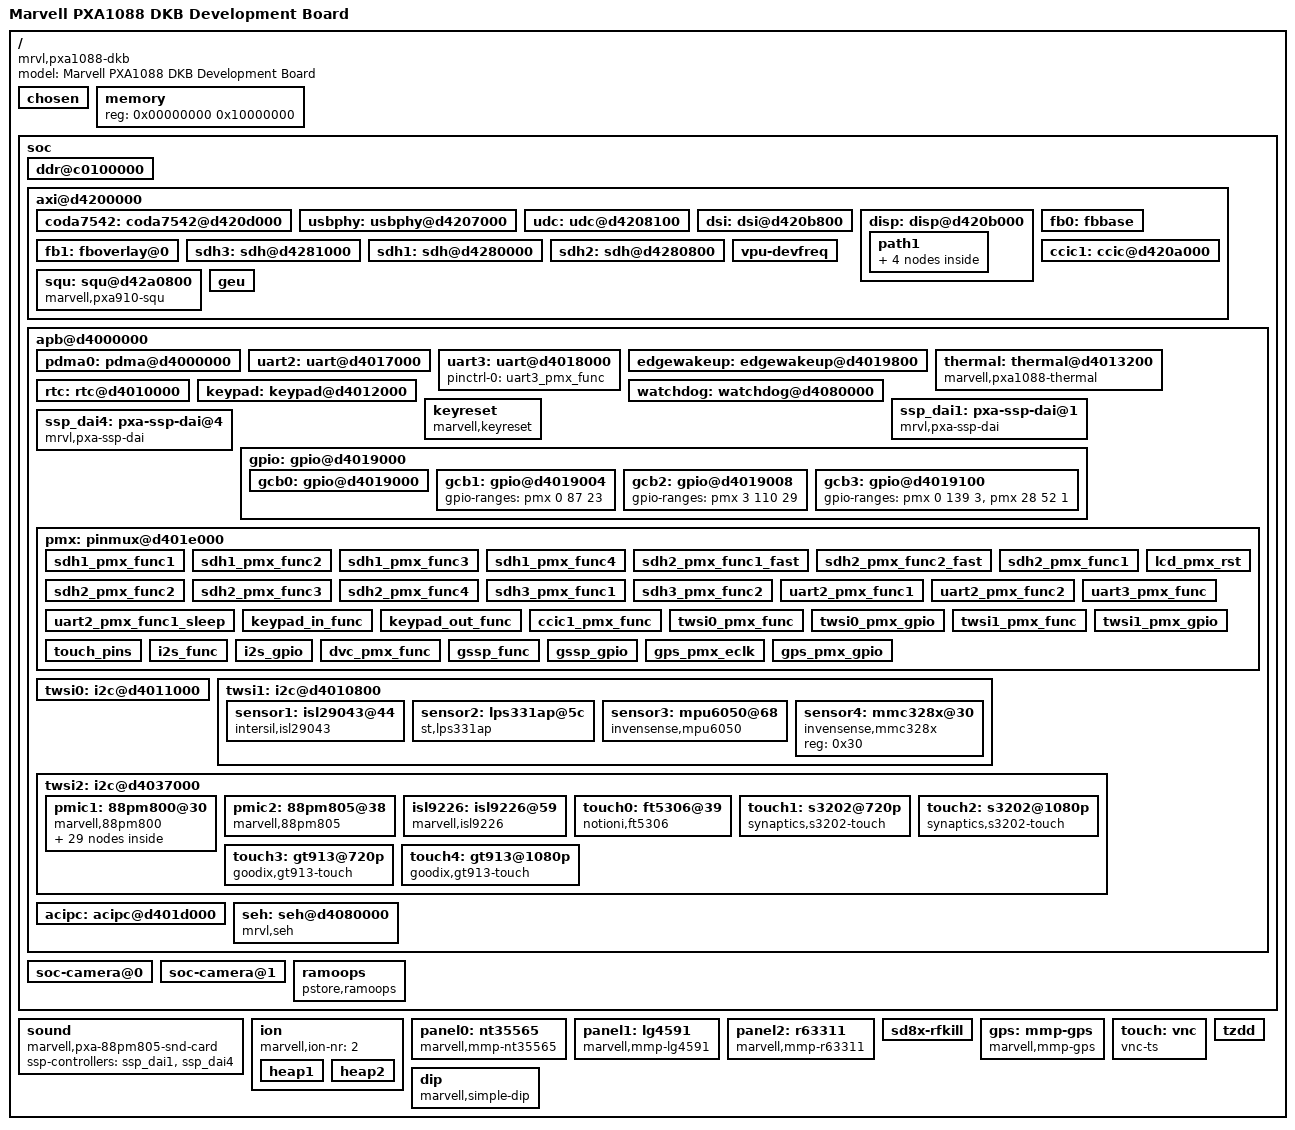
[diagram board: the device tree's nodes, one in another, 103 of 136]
/*
 *  Copyright (C) 2012 Marvell Technology Group Ltd.
 *  Author: Haojian Zhuang <haojian.zhuang@marvell.com>
 *
 *  This program is free software; you can redistribute it and/or modify
 *  it under the terms of the GNU General Public License version 2 as
 *  publishhed by the Free Software Foundation.
 */

/dts-v1/;
/memreserve/ 0x09000000 0x01000000;	/* ION (16MB)*/
/memreserve/ 0x17000000 0x01800000;	/* Frame buffer (24MB) */
/memreserve/ 0x08100000 0x00040000;    /* ramoops buffer (256KB) */
#include "pxa1088.dtsi"
#include <dt-bindings/mmc/pxa_sdhci.h>

/ {
	model = "Marvell PXA1088 DKB Development Board";
	compatible = "mrvl,pxa1088-dkb", "mrvl,pxa1088";

	chosen {
		bootargs = "console=ttyS0,115200 root=/dev/nfs nfsroot=192.168.1.100:/nfsroot/ ip=192.168.1.101:192.168.1.100::255.255.255.0::eth0:on";
	};

	memory {
		reg = <0x00000000 0x10000000>;
	};

	soc {
		ddr@c0100000 {  /* DDR memory controller */
			status = "okay";
		};

		axi@d4200000 {	/* AXI */
			coda7542: coda7542@d420d000 {
				marvell,sram-internal = <1>;
				marvell,nv21_support = <0>;
				status = "okay";
			};

			usbphy: usbphy@d4207000 {
				status = "okay";
			};

			udc: udc@d4208100 {
				status = "okay";
			};

			dsi: dsi@d420b800 {
				marvell,phy-name = "mmp_dsi1";
				marvell,plat-path-name = "mmp_pnpath";
				marvell,dsi-lanes = <2>;
				marvell,burst-mode = <2>;
				marvell,hbp-en;
				status = "okay";
			};

			disp: disp@d420b000 {
				marvell,disp-name = "disp_name";
				marvell,path-num = <1>;
				lpm-qos-d1p = <PM_QOS_CPUIDLE_BLOCK_AXI>;
				status = "okay";
				path1 {
					marvell,path-name = "mmp_pnpath";
					marvell,overlay-num = <2>;
					marvell,overlay-table = <0>, <1>;
					marvell,output-type = <1>;
					marvell,path-config = <0x10>;
					marvell,link-config = <0x1>;
					1080p {
						disp1_clksrc = "pll1_416m";
						dsipll_clksrc = "pll1_832m";
						pn_sclk_clksrc = "dsi_pll";
					};
					720p {
						disp1_clksrc = "pll1_416m";
						dsipll_clksrc = "pll3";
						pn_sclk_clksrc = "disp1";
					};
					qhd {
						disp1_clksrc = "pll1_416m";
						dsipll_clksrc = "pll3";
						pn_sclk_clksrc = "disp1";
					};
					WVGA {
						disp1_clksrc = "pll1_416m";
						dsipll_clksrc = "pll3";
						pn_sclk_clksrc = "dsi_pll";
					};
				};
			};

			fb0: fbbase {
				marvell,fb-name = "mmp-fb";
				marvell,path-name = "mmp_pnpath";
				marvell,overlay-id = <1>;
				marvell,default-pixfmt = <0x108>;
				marvell,buffer-num = <3>;
				marvell,fb-mem = <0x17000000 0x1800000>;
				status = "okay";
			};

			fb1: fboverlay@0 {
				marvell,fb-name = "mmp-fb-overlay.0";
				marvell,path-name = "mmp_pnpath";
				marvell,overlay-id = <0>;
				status = "okay";
			};

			/* eMMC */
			sdh3: sdh@d4281000 {
				pinctrl-names = "default";
				pinctrl-0 = <&sdh3_pmx_func1 &sdh3_pmx_func2>;
				bus-width = <8>;
				non-removable;
				marvell,sdh-pm-runtime-en;
				marvell,sdh-quirks = <(
						SDHCI_QUIRK_BROKEN_ADMA |
						SDHCI_QUIRK_BROKEN_CARD_DETECTION
						)>;
				marvell,sdh-quirks2 = <(SDHCI_QUIRK2_BUS_CLK_GATE_ENABLED)>;
				marvell,sdh-host-caps = <(MMC_CAP_1_8V_DDR)>;
				marvell,sdh-host-caps2 = <(MMC_CAP2_DISABLE_BLK_ASYNC)>;
				marvell,sdh-flags = <(
						PXA_FLAG_SD_8_BIT_CAPABLE_SLOT |
						PXA_FLAG_ENABLE_CLOCK_GATING |
						PXA_FLAG_TX_SEL_BUS_CLK
					      )>;
				/* prop "sdh-dtr-data": <timing preset_rate src_rate tx_delay rx_delay> */
				marvell,sdh-dtr-data = <PXA_MMC_TIMING_LEGACY PXA_SDH_DTR_26M PXA_SDH_DTR_104M 0 0>,
						<PXA_MMC_TIMING_MMC_HS PXA_SDH_DTR_52M PXA_SDH_DTR_104M 0 0>,
						<PXA_MMC_TIMING_UHS_DDR50 PXA_SDH_DTR_52M PXA_SDH_DTR_104M 0xd4 0>,
						<PXA_MMC_TIMING_MAX PXA_SDH_DTR_PS_NONE PXA_SDH_DTR_104M 0 0>;
				status = "okay";
			};

			/* SD card */
			sdh1: sdh@d4280000 {
				pinctrl-names = "default";
				pinctrl-0 = <&sdh1_pmx_func1 &sdh1_pmx_func2 &sdh1_pmx_func3 &sdh1_pmx_func4>;
				vqmmc-supply	= <&ldo12>;
				vmmc-supply	= <&ldo13>;
				cd-gpios = <&gpio 91 0>;
				cd-inverted;
				bus-width = <4>;
				wp-inverted;
				marvell,sdh-pm-runtime-en;
				marvell,sdh-host-caps-disable = <(MMC_CAP_UHS_SDR104)>;
				marvell,sdh-quirks = <(
						SDHCI_QUIRK_INVERTED_WRITE_PROTECT |
						SDHCI_QUIRK_BROKEN_CARD_DETECTION
						)>;
				marvell,sdh-quirks2 = <(SDHCI_QUIRK2_BUS_CLK_GATE_ENABLED)>;
				marvell,sdh-flags = <(
						PXA_FLAG_TX_SEL_BUS_CLK |
						PXA_FLAG_ENABLE_CLOCK_GATING
					      )>;
				/* prop "sdh-dtr-data": <timing preset_rate src_rate tx_delay rx_delay> */
				marvell,sdh-dtr-data = <PXA_MMC_TIMING_LEGACY PXA_SDH_DTR_26M PXA_SDH_DTR_104M 0 0>,
						<PXA_MMC_TIMING_SD_HS PXA_SDH_DTR_52M PXA_SDH_DTR_104M 0 0>,
						<PXA_MMC_TIMING_UHS_DDR50 PXA_SDH_DTR_52M PXA_SDH_DTR_104M 0 0>,
						<PXA_MMC_TIMING_MAX PXA_SDH_DTR_PS_NONE PXA_SDH_DTR_104M 0 0>;
				status = "okay";
			};

			/* SDIO */
			sdh2: sdh@d4280800 {
				pinctrl-names = "default", "fast";
				pinctrl-0 = <&sdh2_pmx_func1 &sdh2_pmx_func2 &sdh2_pmx_func3 &sdh2_pmx_func4>;
				pinctrl-1 = <&sdh2_pmx_func1_fast &sdh2_pmx_func2_fast &sdh2_pmx_func3 &sdh2_pmx_func4>;
				bus-width = <4>;
				marvell,sdh-quirks = <(SDHCI_QUIRK_BROKEN_CARD_DETECTION)>;
				marvell,sdh-quirks2 = <(
						SDHCI_QUIRK2_BUS_CLK_GATE_ENABLED |
						SDHCI_QUIRK2_SDIO_SW_CLK_GATE
						)>;
				marvell,sdh-pm-caps = <(MMC_PM_KEEP_POWER)>;
				marvell,sdh-host-caps2 = <(MMC_CAP2_NO_VOLTAGE_SWITCH)>;
				marvell,sdh-flags = <(
						PXA_FLAG_WAKEUP_HOST |
						PXA_FLAG_ENABLE_CLOCK_GATING |
						PXA_FLAG_TX_SEL_BUS_CLK |
						PXA_FLAG_EN_PM_RUNTIME |
						PXA_FLAG_DISABLE_PROBE_CDSCAN
					      )>;
				/* prop "sdh-dtr-data": <timing preset_rate src_rate tx_delay rx_delay> */
				marvell,sdh-dtr-data = <PXA_MMC_TIMING_LEGACY PXA_SDH_DTR_26M PXA_SDH_DTR_104M 0 0>,
						<PXA_MMC_TIMING_SD_HS PXA_SDH_DTR_45M PXA_SDH_DTR_89M 0 0>,
						<PXA_MMC_TIMING_MAX PXA_SDH_DTR_PS_NONE PXA_SDH_DTR_89M 0 0>;
				status = "okay";
			};

			ccic1: ccic@d420a000 {
				 pinctrl-names = "default";
				 pinctrl-0 = <&ccic1_pmx_func>;
				 pwdn-gpios = <&gpio 80 0>;
				 reset-gpios = <&gpio 81 0>;
				 af_2v8-supply = <&ldo17>;
				 avdd_2v8-supply = <&ldo16>;
				 status = "okay";
			};

			squ: squ@d42a0800 {
				compatible = "marvell,pxa910-squ";
				reg = <0xd42a0800 0x100>;
				interrupts = <0 46 0x4>;
				#dma-cells = <1>;
				asram = <&sram>;
			};
			vpu-devfreq {
				status = "okay";
			};
			geu: geu {
				status = "okay";
			};
		};

		apb@d4000000 {
			pdma0: pdma@d4000000 {
				status = "okay";
			};

			uart2: uart@d4017000 {
				pinctrl-names = "default", "sleep";
				pinctrl-0 = <&uart2_pmx_func1 &uart2_pmx_func2>;
				pinctrl-1 = <&uart2_pmx_func1_sleep &uart2_pmx_func2>;
				edge-wakeup-gpio = <47>; /* GPIO47: UART rx pin */
				status = "okay";
			};

			uart3: uart@d4018000 {
				pinctrl-names = "default";
				pinctrl-0 = <&uart3_pmx_func>;
				status = "okay";
			};

			edgewakeup: edgewakeup@d4019800 {
				status = "okay";
			};

			thermal: thermal@d4013200 {
				compatible = "marvell,pxa1088-thermal";
				reg = <0xd4013200 0x50>;
				interrupts = <0 60 0x4>;
				status = "ok";
			};

			rtc: rtc@d4010000 {
				status = "okay";
			};

			watchdog: watchdog@d4080000 {
				status = "okay";
			};

			keypad: keypad@d4012000 {
				keypad,num-rows = <4>;
				keypad,num-columns = <8>;
				linux,keymap = <0x0000000e
						0x0001008b
						0x000200d4
						0x0100008b
						0x01010066
						0x010200d4
						0x020000e7
						0x020100d9
						0x020200f0
						0x03000073
						0x03010072
						0x030200f0>;
				marvell,debounce-interval = <30>;
				pinctrl-names = "default";
				pinctrl-0 = <&keypad_in_func  &keypad_out_func>;
				status = "okay";
			};

			keyreset {
				compatible = "marvell,keyreset";
				keys-down = <0x73 0x72>;
				keyreset-need-panic;
			};

			ssp_dai1: pxa-ssp-dai@1 {
				compatible = "mrvl,pxa-ssp-dai";
				reg = <0x1 0x0>;
				port = <&ssp1>;
				pinctrl-names = "default","ssp";
				pinctrl-0 = <&i2s_gpio>;
				pinctrl-1 = <&i2s_func>;
				ssp-gpio = <&gpio 21 0 &gpio 22 0 &gpio 23 0 &gpio 24 0>;
				dmas = <&squ 1
					&squ 0>;
				dma-names = "rx", "tx";
				asram = <&sram>;
				platform_driver_name = "tdma_platform";
				burst_size = <4>;
				playback_period_bytes = <4096>;
				playback_buffer_bytes = <20480>;
				capture_period_bytes = <4096>;
				capture_buffer_bytes = <20480>;
			};

			ssp_dai4: pxa-ssp-dai@4 {
				compatible = "mrvl,pxa-ssp-dai";
				reg = <0x4 0x0>;
				port = <&ssp4>;
				pinctrl-names = "default","ssp";
				pinctrl-0 = <&gssp_gpio>;
				pinctrl-1 = <&gssp_func>;
				ssp-gpio = <&gpio 25 0 &gpio 26 0 &gpio 27 0 &gpio 28 0>;
				dmas = <&pdma0 6 0
					&pdma0 7 0>;
				dma-names = "rx", "tx";
				platform_driver_name = "pdma_platform";
				burst_size = <8>;
				playback_period_bytes = <4096>;
				playback_buffer_bytes = <131072>;
				capture_period_bytes = <4096>;
				capture_buffer_bytes = <131072>;
			};

			gpio: gpio@d4019000 {
				status = "okay";
				/*
				 * In theorical, some gpios could be routed to
				 * multiple pins. So define the gpio-ranges in
				 * board file, not silicon file.
				 */
				gcb0: gpio@d4019000 {
					/* gpio offset, pin offset, nr pins */
					gpio-ranges = <&pmx 0 55 1 &pmx 1 30 1 &pmx 2 57 30>;
				};
				gcb1: gpio@d4019004 {
					gpio-ranges = <&pmx 0 87 23>;
				};
				gcb2: gpio@d4019008 {
					gpio-ranges = <&pmx 3 110 29>;
				};
				gcb3: gpio@d4019100 {
					gpio-ranges = <&pmx 0 139 3  &pmx 28 52 1>;
				};
			};
			pmx: pinmux@d401e000 {
				/* pin base, nr pins & gpio function */
				pinctrl-single,gpio-range = <
					/*
					 * GPIO number is hardcoded for range at here.
					 * In gpio chip, GPIO number is not hardcoded for range.
					 * Since one gpio pin may be routed to multiple pins,
					 * define these gpio range in pxa910-dkb.dts not pxa910.dtsi.
					 */
					&range 55 1 0	/* GPIO0 */
					&range 30 1 1	/* GPIO1 */
					&range 57 53 0	/* GPIO2 ~ GPIO54 */
					&range 110 32 0 /* GPIO67 ~ GPIO98 */
					&range 52 1 0	/* GPIO124 */
				>;

				/* MFP_PULL_LOW | MFP_LPM_FLOAT */
				sdh1_pmx_func1: sdh1_pmx_func1 {
					pinctrl-single,pins = <
						MMC1_DAT7 AF0
						MMC1_DAT6 AF0
						MMC1_DAT5 AF0
						MMC1_DAT4 AF0
						MMC1_WP AF0
					>;
					DS_MEDIUM;PULL_DOWN;EDGE_NONE;LPM_FLOAT;
				};

				/* no pull, no LPM */
				sdh1_pmx_func2: sdh1_pmx_func2 {
					pinctrl-single,pins = <
						MMC1_DAT3 AF0
						MMC1_DAT2 AF0
						MMC1_DAT1 AF0
						MMC1_DAT0 AF0
						MMC1_CMD AF0
					>;
					MFP_DEFAULT;
				};

				/* MFP_LPM_DRIVE_LOW */
				sdh1_pmx_func3: sdh1_pmx_func3 {
					pinctrl-single,pins = <
						MMC1_CLK AF0
					>;
					MFP_LPM_DRIVE_LOW;
				};

				/* MFP_PULL_HIGH */
				sdh1_pmx_func4: sdh1_pmx_func4 {
					pinctrl-single,pins = <
						MMC1_CD AF0
					>;
					DS_MEDIUM;PULL_HIGH;EDGE_NONE;LPM_NONE;
				};

				sdh2_pmx_func1_fast: sdh2_pmx_func1_fast {
						pinctrl-single,pins = <
							GPIO37 AF1
							GPIO38 AF1
							GPIO39 AF1
							GPIO40 AF1
							GPIO41 AF1
						>;
						DS_FAST;PULL_NONE;EDGE_NONE;LPM_NONE;
				};

				sdh2_pmx_func2_fast: sdh2_pmx_func2_fast {
						pinctrl-single,pins = <
							GPIO42 AF1
						>;
						DS_FAST;PULL_NONE;EDGE_NONE;LPM_DRIVE_LOW;
				};

				sdh2_pmx_func1: sdh2_pmx_func1 {
						pinctrl-single,pins = <
							GPIO37 AF1
							GPIO38 AF1
							GPIO39 AF1
							GPIO40 AF1
							GPIO41 AF1
						>;
						MFP_DEFAULT;
				};

				sdh2_pmx_func2: sdh2_pmx_func2 {
						pinctrl-single,pins = <
							GPIO42 AF1
						>;
						DS_SLOW0;PULL_NONE;EDGE_NONE;LPM_DRIVE_LOW;
				};

				sdh2_pmx_func3: sdh2_pmx_func3 {
						pinctrl-single,pins = <
							GPIO7 AF0
							GPIO71 AF0
						>;
						DS_MEDIUM;PULL_FLOAT;EDGE_NONE;LPM_NONE;
				};

				sdh2_pmx_func4: sdh2_pmx_func4 {
						pinctrl-single,pins = <
							GPIO8 AF0
							GPIO9 AF0
						>;
						DS_MEDIUM;PULL_LOW;EDGE_NONE;LPM_NONE;
				};

				/* no pull, no LPM */
				sdh3_pmx_func1: sdh3_pmx_func1 {
					pinctrl-single,pins = <
						ND_IO7 AF1
						ND_IO6 AF1
						ND_IO5 AF1
						ND_IO4 AF1
						ND_IO3 AF1
						ND_IO2 AF1
						ND_IO1 AF1
						ND_IO0 AF1
						ND_CLE_SM_OEN AF1
						SM_BEN0 AF2
					>;
					MFP_DEFAULT;
				};

				/* MFP_LPM_DRIVE_LOW */
				sdh3_pmx_func2: sdh3_pmx_func2 {
					pinctrl-single,pins = <
						SM_SCLK AF1
					>;
					MFP_LPM_DRIVE_LOW;
				};

				/* MFP_LPM_FLOAT */
				lcd_pmx_rst: lcd_pmx_rst {
					pinctrl-single,pins = <
						0x78 0x1
					>;
					/* drive strength set value, mask */
					pinctrl-single,drive-strength = <0x1000 0x1800>;
					/* bias set value, enable, disable, mask */
					pinctrl-single,bias-pullup = <0x8000 0xc000 0x8000 0xc000>;
					pinctrl-single,bias-pulldown = <0x8000 0xa000 0x8000 0xa000>;
					/* input schmitt set value, mask */
					pinctrl-single,input-schmitt = <0 0x30>;
					/* set value, enable, disable, mask */
					pinctrl-single,input-schmitt-enable = <0x40 0 0x40 0x40>;
					/* lpm output set value, mask */
					pinctrl-single,lpm-output = <0x288 0x388>;
				};

				uart2_pmx_func1: uart2_pmx_func1 {
					pinctrl-single,pins = <
						GPIO47 AF6
					>;
					MFP_DEFAULT;
				};

				uart2_pmx_func2: uart2_pmx_func2 {
					pinctrl-single,pins = <
						GPIO48 AF6
					>;
					MFP_DEFAULT;
				};

				uart2_pmx_func1_sleep: uart2_pmx_func1_sleep {
					pinctrl-single,pins = <
						GPIO47 AF6
					>;
					DS_MEDIUM;PULL_NONE;EDGE_BOTH;LPM_NONE;
				};

				uart3_pmx_func: uart3_pmx_func {
					pinctrl-single,pins = <
						GPIO45 AF1
						GPIO46 AF1
					>;
					MFP_DEFAULT;
				};

				keypad_in_func: keypad_in_func {
					pinctrl-single,pins = <
						0x0dc 0x1	/* GPIO000_KP_MKIN0 */
						0x0e4 0x1	/* GPIO002_KP_MKIN1 */
						0x0ec 0x1	/* GPIO004_KP_MKIN2 */
						0x0f4 0x1	/* GPIO006_KP_MKIN3 */
					>;
					pinctrl-single,drive-strength = <0x1000 0x1800>;
					pinctrl-single,bias-pullup = <0 0xc000 0 0xc000>;
					pinctrl-single,bias-pulldown = <0 0xa000 0 0xa000>;
					pinctrl-single,input-schmitt = <0 0x30>;
					pinctrl-single,input-schmitt-enable = <0x40 0 0x40 0x40>;
					pinctrl-single,lpm-output = <0x0 0x388>;
				};

				keypad_out_func: keypad_out_func {
					pinctrl-single,pins = <
						0x0e0 0x1	/* GPIO001_KP_MKOUT0 */
						0x0e8 0x1	/* GPIO002_KP_MKOUT1 */
						0x0f0 0x1	/* GPIO004_KP_MKOUT2 */
					>;
					pinctrl-single,drive-strength = <0x1000 0x1800>;
					pinctrl-single,bias-pullup = <0x8000 0xc000 0x8000 0xc000>;
					pinctrl-single,bias-pulldown = <0x8000 0xa000 0x8000 0xa000>;
					pinctrl-single,input-schmitt = <0 0x30>;
					pinctrl-single,input-schmitt-enable = <0x40 0 0x40 0x40>;
					pinctrl-single,lpm-output = <0x308 0x388>;
				};

				ccic1_pmx_func: ccic1_pmx_func {
					pinctrl-single,pins = <
						 0x1e0 0x1
				    >;
					pinctrl-single,drive-strength = <0x1000 0x1800>;
					pinctrl-single,bias-pullup = <0 0xc000 0 0xc000>;
					pinctrl-single,bias-pulldown = <0 0xa000 0 0xa000>;
					pinctrl-single,input-schmitt = <0 0x30>;
					pinctrl-single,input-schmitt-enable = <0x40 0 0x40 0x40>;
					pinctrl-single,lpm-output = <0x0 0x388>;
				};

				twsi0_pmx_func: twsi0_pmx_func {
					pinctrl-single,pins = <
						0x1b0 0x2
						0x1b4 0x2
					>;
					MFP_LPM_FLOAT;
				};
				twsi0_pmx_gpio: twsi0_pmx_gpio {
					pinctrl-single,pins = <
						0x1b0 0x0
						0x1b4 0x0
					>;
					MFP_LPM_FLOAT;
				};
				twsi1_pmx_func: twsi1_pmx_func {
					pinctrl-single,pins = <
						0x208 0x5
						0x20c 0x5
					>;
					MFP_LPM_FLOAT;
				};
				twsi1_pmx_gpio: twsi1_pmx_gpio {
					pinctrl-single,pins = <
						0x208 0x0
						0x20c 0x0
					>;
					MFP_LPM_FLOAT;
				};

				touch_pins: touch_pins {
					pinctrl-single,pins = <
						0x011c 0x0
						0x0120 0x0
					>;
					pinctrl-single,drive-strength = <0x1000 0x1800>;
					pinctrl-single,bias-pullup = <0 0xc000 0 0xc000>;
					pinctrl-single,bias-pulldown = <0 0xa000 0 0xa000>;
					pinctrl-single,input-schmitt = <0 0x30>;
					pinctrl-single,input-schmitt-enable = <0x40 0 0x40 0x40>;
					pinctrl-single,lpm-output = <0x0 0x388>;

				};

				i2s_func: i2s_func {
					pinctrl-single,pins = <
						0x0130 0x1
						0x0134 0x1
						0x0138 0x1
						0x013c 0x1
					>;
					pinctrl-single,drive-strength = <0x1000 0x1800>;
					pinctrl-single,bias-pullup = <0 0xc000 0 0xc000>;
					pinctrl-single,bias-pulldown = <0 0xa000 0 0xa000>;
					pinctrl-single,input-schmitt = <0 0x30>;
					pinctrl-single,input-schmitt-enable = <0x40 0 0x40 0x40>;
					pinctrl-single,lpm-output = <0x0 0x388>;
				};
				i2s_gpio: i2s_gpio {
					pinctrl-single,pins = <
						0x0130 0x0
						0x0134 0x0
						0x0138 0x0
						0x013c 0x0
					>;
					/* drive strength set value, mask */
					pinctrl-single,drive-strength = <0x1000 0x1800>;
					/* bias set value, enable, disable, mask */
					pinctrl-single,bias-pullup = <0 0xc000 0 0xc000>;
					pinctrl-single,bias-pulldown = <0 0xa000 0 0xa000>;
					/* input schmitt set value, mask */
					pinctrl-single,input-schmitt = <0 0x30>;
					/* set value, enable, disable, mask */
					pinctrl-single,input-schmitt-enable = <0x40 0 0x40 0x40>;
					/* lpm output set value, mask */
					pinctrl-single,lpm-output = <0x288 0x388>;
				};
				/* no pull, no LPM */
				dvc_pmx_func: dvc_pmx_func {
					pinctrl-single,pins = <
						0x188 0x6
						0x18c 0x6
					>;
					/* drive strength set value, mask */
					pinctrl-single,drive-strength = <0x1000 0x1800>;
					/* bias set value, enable, disable, mask */
					pinctrl-single,bias-pullup = <0 0xc000 0 0xc000>;
					pinctrl-single,bias-pulldown = <0 0xa000 0 0xa000>;
					/* input schmitt set value, mask */
					pinctrl-single,input-schmitt = <0 0x30>;
					/* set value, enable, disable, mask */
					pinctrl-single,input-schmitt-enable = <0x40 0 0x40 0x40>;
					/* lpm output set value, mask */
					pinctrl-single,lpm-output = <0 0x388>;
				};
				gssp_func: gssp_func {
					pinctrl-single,pins = <
						0x0140 0x1
						0x0144 0x1
						0x0148 0x1
						0x014c 0x1
					>;
					pinctrl-single,drive-strength = <0x1000 0x1800>;
					pinctrl-single,bias-pullup = <0 0xc000 0 0xc000>;
					pinctrl-single,bias-pulldown = <0 0xa000 0 0xa000>;
					pinctrl-single,input-schmitt = <0 0x30>;
					pinctrl-single,input-schmitt-enable = <0x40 0 0x40 0x40>;
					pinctrl-single,lpm-output = <0x0 0x388>;
				};
				gssp_gpio: gssp_gpio {
					pinctrl-single,pins = <
						0x0140 0x0
						0x0144 0x0
						0x0148 0x0
						0x014c 0x0
					>;
					/* drive strength set value, mask */
					pinctrl-single,drive-strength = <0x1000 0x1800>;
					/* bias set value, enable, disable, mask */
					pinctrl-single,bias-pullup = <0 0xc000 0 0xc000>;
					pinctrl-single,bias-pulldown = <0 0xa000 0 0xa000>;
					/* input schmitt set value, mask */
					pinctrl-single,input-schmitt = <0 0x30>;
					/* set value, enable, disable, mask */
					pinctrl-single,input-schmitt-enable = <0x40 0 0x40 0x40>;
					/* lpm output set value, mask */
					pinctrl-single,lpm-output = <0x288 0x388>;
				};
				gps_pmx_eclk: gps_pmx_eclk {
					/* eclk */
					pinctrl-single,pins = <
						0x0210 0x5
					>;
					pinctrl-single,drive-strength = <0x1000 0x1800>;
					pinctrl-single,bias-pullup = <0 0xc000 0 0xc000>;
					pinctrl-single,bias-pulldown = <0 0xa000 0 0xa000>;
					pinctrl-single,input-schmitt = <0 0x30>;
					pinctrl-single,input-schmitt-enable = <0x40 0 0x40 0x40>;
					pinctrl-single,lpm-output = <0x0 0x388>;
				};
				gps_pmx_gpio: gps_pmx_gpio {
					/* gpio */
					pinctrl-single,pins = <
						0x0210 0x0
					>;
					pinctrl-single,drive-strength = <0x1000 0x1800>;
					pinctrl-single,bias-pullup = <0 0xc000 0 0xc000>;
					pinctrl-single,bias-pulldown = <0 0xa000 0 0xa000>;
					pinctrl-single,input-schmitt = <0 0x30>;
					pinctrl-single,input-schmitt-enable = <0x40 0 0x40 0x40>;
					pinctrl-single,lpm-output = <0x0 0x388>;
				};
			};

			twsi0: i2c@d4011000 {
				pinctrl-names = "default","gpio";
				pinctrl-0 = <&twsi0_pmx_func>;
				pinctrl-1 = <&twsi0_pmx_gpio>;
				i2c-gpio = <&gpio 53 0 &gpio 54 0>;
				status = "okay";
			};

			twsi1: i2c@d4010800 {
				pinctrl-names = "default","gpio";
				pinctrl-0 = <&twsi1_pmx_func>;
				pinctrl-1 = <&twsi1_pmx_gpio>;
				i2c-gpio = <&gpio 87 0 &gpio 88 0>;
				status = "okay";
			};

			twsi1: i2c@d4010800 {
				status = "okay";

				sensor1: isl29043@44 {
					compatible = "intersil,isl29043";
					reg = <0x44>;
					interrupt-parent = <&gpio>;
					interrupts = <14 0x1>;
					irq-gpios = <&gpio 14 0>;
					intersil,wakup-gpios = <&gpio 14 0>;
					avdd-supply = <&ldo11>;
				};

				sensor2: lps331ap@5c {
					compatible = "st,lps331ap";
					reg = <0x5c>;
					lps331ap,poll_interval = <1000>;
					avdd-supply = <&ldo11>;
				};

				sensor3: mpu6050@68 {
					compatible = "invensense,mpu6050";
					reg = <0x68>;
					interrupt-parent = <&gpio>;
					interrupts = <95 0x2>;
					invensense,irq-gpios = <&gpio 95 0x00>;
					avdd-supply = <&ldo11>;
				};

				sensor4: mmc328x@30 {
					compatible = "invensense,mmc328x";
					reg = <0x30>;
				};
			};

			twsi2: i2c@d4037000 {
				status = "okay";

				pmic1: 88pm800@30 {
					compatible = "marvell,88pm800";
					reg = <0x30>;
					interrupts = <0 4 0x4>;
					interrupt-parent = <&gic>;
					interrupt-controller;
					#interrupt-cells = <1>;
					marvell,88pm800-irq-write-clear;

					marvell,88pm800-power-page-addr = <0x31>;
					marvell,88pm800-gpadc-page-addr = <0x32>;

					regulators {
						compatible = "marvell,88pm80x-regulator";

						BUCK1 {
							regulator-compatible = "88PM800-BUCK1";
							regulator-min-microvolt = <600000>;
							regulator-max-microvolt = <3950000>;
							regulator-boot-on;
							regulator-always-on;
						};
						BUCK2 {
							regulator-compatible = "88PM800-BUCK2";
							regulator-min-microvolt = <600000>;
							regulator-max-microvolt = <3950000>;
							regulator-boot-on;
							regulator-always-on;
						};
						BUCK3 {
							regulator-compatible = "88PM800-BUCK3";
							regulator-min-microvolt = <600000>;
							regulator-max-microvolt = <3950000>;
							regulator-boot-on;
							regulator-always-on;
						};
						BUCK4 {
							regulator-compatible = "88PM800-BUCK4";
							regulator-min-microvolt = <600000>;
							regulator-max-microvolt = <3950000>;
							regulator-boot-on;
							regulator-always-on;
						};
						BUCK5 {
							regulator-compatible = "88PM800-BUCK5";
							regulator-min-microvolt = <600000>;
							regulator-max-microvolt = <3950000>;
							regulator-always-on;
						};
						LDO1 {
							regulator-compatible = "88PM800-LDO1";
							regulator-min-microvolt = <600000>;
							regulator-max-microvolt = <1500000>;
						};
						LDO2: LDO2 {
							regulator-compatible = "88PM800-LDO2";
							regulator-min-microvolt = <1700000>;
							regulator-max-microvolt = <2800000>;
							regulator-boot-on;
						};
						LDO3 {
							regulator-compatible = "88PM800-LDO3";
							regulator-min-microvolt = <1200000>;
							regulator-max-microvolt = <3300000>;
							regulator-boot-on;
							regulator-always-on;
						};
						LDO4 {
							regulator-compatible = "88PM800-LDO4";
							regulator-min-microvolt = <1200000>;
							regulator-max-microvolt = <3300000>;
						};
						LDO5 {
							regulator-compatible = "88PM800-LDO5";
							regulator-min-microvolt = <1200000>;
							regulator-max-microvolt = <3300000>;
							regulator-boot-on;
							regulator-always-on;
						};
						wib_3v3: LDO6 {
							regulator-compatible = "88PM800-LDO6";
							regulator-min-microvolt = <1200000>;
							regulator-max-microvolt = <3300000>;
							regulator-boot-on;
							regulator-always-on;
						};
						LDO7 {
							regulator-compatible = "88PM800-LDO7";
							regulator-min-microvolt = <1200000>;
							regulator-max-microvolt = <3300000>;
							regulator-boot-on;
							regulator-always-on;
						};
						ldo8: LDO8 {
							regulator-compatible = "88PM800-LDO8";
							regulator-min-microvolt = <1200000>;
							regulator-max-microvolt = <3300000>;
							regulator-boot-on;
						};
						wib_1v8: LDO9 {
							regulator-compatible = "88PM800-LDO9";
							regulator-min-microvolt = <1200000>;
							regulator-max-microvolt = <3300000>;
							regulator-boot-on;
							regulator-always-on;
						};
						LDO10 {
							regulator-compatible = "88PM800-LDO10";
							regulator-min-microvolt = <1200000>;
							regulator-max-microvolt = <3300000>;
						};
						ldo11: LDO11 {
							regulator-compatible = "88PM800-LDO11";
							regulator-min-microvolt = <1200000>;
							regulator-max-microvolt = <3300000>;
							/* FIXME: remove it later after add dynamic power on/off */
							regulator-always-on;
						};
						ldo12: LDO12 {
							regulator-compatible = "88PM800-LDO12";
							regulator-min-microvolt = <1200000>;
							regulator-max-microvolt = <3300000>;
						};
						ldo13: LDO13 {
							regulator-compatible = "88PM800-LDO13";
							regulator-min-microvolt = <1200000>;
							regulator-max-microvolt = <3300000>;
						};
						LDO14 {
							regulator-compatible = "88PM800-LDO14";
							regulator-min-microvolt = <1200000>;
							regulator-max-microvolt = <3300000>;
							regulator-boot-on;
							regulator-always-on;
						};
						ldo15: LDO15 {
							regulator-compatible = "88PM800-LDO15";
							regulator-min-microvolt = <1200000>;
							regulator-max-microvolt = <3300000>;
						};
						ldo16: LDO16 {
							regulator-compatible = "88PM800-LDO16";
							regulator-min-microvolt = <1200000>;
							regulator-max-microvolt = <3300000>;
						};
						ldo17: LDO17 {
							regulator-compatible = "88PM800-LDO17";
							regulator-min-microvolt = <1200000>;
							regulator-max-microvolt = <3300000>;
						};
						LDO18 {
							regulator-compatible = "88PM800-LDO18";
							regulator-min-microvolt = <1700000>;
							regulator-max-microvolt = <3300000>;
							regulator-boot-on;
							regulator-always-on;
						};
						LDO19 {
							regulator-compatible = "88PM800-LDO19";
							regulator-min-microvolt = <1700000>;
							regulator-max-microvolt = <3300000>;
							regulator-boot-on;
							regulator-always-on;
						};
					};

					vibrator: vibrator {
						compatible = "marvell,88pm80x-vibrator";
						min-timeout = <10>;
						duty-cycle = <0x3f>;
					};

					headset {
						compatible = "marvell,88pm80x-headset";
						marvell,switch-name = "h2w";
						marvell,headset-flag = <1>;
						marvell,hook-press-th = <60>;
						marvell,vol-up-press-th = <250>;
						marvell,vol-down-press-th = <500>;
						marvell,mic-det-th = <600>;
						marvell,press-release-th = <600>;
						marvell,micbias-supply = <&LDO2>;
					};

					usb: usb {
						compatible = "marvell,88pm80x-usb";
						vbus-gpio = <2>;
						id-gpadc = <0xff>;
					};

					dvc {
						compatible = "marvell,88pm8xx-dvc";
						/* pm800 dvc affect buck1/4, affected 32bit = (1 << 3) | (1 << 0)*/
						dvc-affected-buckbits = <9>;
						pinctrl-names = "default";
						pinctrl-0 = <&dvc_pmx_func>;
					};
				};
				pmic2: 88pm805@38 {
					compatible = "marvell,88pm805";
					reg = <0x38>;
					interrupt-parent = <&gpio>;
					interrupts = <124 0x1>;
					marvell,88pm805-irq-write-clear;
				};

				isl9226: isl9226@59{
						compatible = "marvell,isl9226";
						reg = <0x59>;
						default_input_current = <95>;
						usb_input_current = <475>;
						ac_input_current = <950>;
						eoc_current = <240>;
						prechg_current = <120>;
						prechg_voltage = <3000>;
					};

				touch0: ft5306@39 {
					compatible = "notioni,ft5306";
					pinctrl-names = "default"; pinctrl-0 = <&touch_pins>;
					reg = <0x39>;
					ft5306,abs-x-max = <540>;
					ft5306,abs-y-max = <960>;
					ft5306,abs-flags = <0>;
					power-ldo-supply = <&ldo8>;
					reset-gpio = <&gpio 16 1>;
					interrupt-parent = <&gpio>;
					interrupts = <17 0x1>;
				};

				touch1: s3202@720p {
					compatible = "synaptics,s3202-touch";
					pinctrl-names = "default"; pinctrl-0 = <&touch_pins>;
					reg = <0x22>;
					interrupt-parent = <&gpio>;
					interrupts = <17 0x1>;
					/* IRQF_ONESHOT | IRQF_TRIGGER_FALLING */
					synaptics,irq-flags =  <0x2002>;
					synaptics,irq-gpios = <&gpio 17 0>;
					synaptics,reset-gpios = <&gpio 16 0>;
					synaptics,sensor_res_x = <720>;
					synaptics,sensor_res_y = <1280>;
					synaptics,sensor_max_x = <798>;
					synaptics,sensor_max_y = <1392>;
					synaptics,sensor_margin_x = <39>;
					synaptics,sensor_margin_y = <0>;
					avdd-supply = <&ldo8>;
				};

				touch2: s3202@1080p {
					compatible = "synaptics,s3202-touch";
					pinctrl-names = "default"; pinctrl-0 = <&touch_pins>;
					reg = <0x22>;
					interrupt-parent = <&gpio>;
					interrupts = <17 0x1>;
					/* IRQF_ONESHOT | IRQF_TRIGGER_FALLING */
					synaptics,irq-flags =  <0x2002>;
					synaptics,irq-gpios = <&gpio 17 0>;
					synaptics,reset-gpios = <&gpio 16 0>;
					synaptics,sensor_res_x = <1080>;
					synaptics,sensor_res_y = <1920>;
					synaptics,sensor_max_x = <1080>;
					synaptics,sensor_max_y = <2070>;
					synaptics,sensor_margin_x = <0>;
					synaptics,sensor_margin_y = <0>;
					avdd-supply = <&ldo8>;
				};

				touch3: gt913@720p {
					compatible = "goodix,gt913-touch";
					pinctrl-names = "default"; pinctrl-0 = <&touch_pins>;
					reg = <0x5d>;
					interrupt-parent = <&gpio>;
					interrupts = <17 0x1>;
					irq-gpios = <&gpio 17 0>;
					reset-gpios = <&gpio 16 0>;
					goodix,max-height = <1280>;
					goodix,max-width = <720>;
					avdd-supply = <&ldo8>;
				};

				touch4: gt913@1080p {
					compatible = "goodix,gt913-touch";
					pinctrl-names = "default"; pinctrl-0 = <&touch_pins>;
					reg = <0x5d>;
					interrupt-parent = <&gpio>;
					interrupts = <17 0x1>;
					irq-gpios = <&gpio 17 0>;
					reset-gpios = <&gpio 16 0>;
					goodix,max-height = <1920>;
					goodix,max-width = <1080>;
					avdd-supply = <&ldo8>;
				};
			};

			acipc: acipc@d401d000 {
				status = "okay";
			};

			seh: seh@d4080000 {
				compatible = "mrvl,seh";
				reg = <0xd4080000 0x100>;
				interrupts = <0 35 0x4>;
				interrupt-names = "WDT";
				watchdog-type = <0>; /* wdt timer */
				status = "okay";
			};
		};

		soc-camera@0 {
			status = "okay";
		};

		soc-camera@1 {
			status = "okay";
		};

		/*
		 * ramoops:
		 * 256 KB memory starts at 0x8100000
		 * pstore dump: 2 chunks, totall 64 KB, 32 KB each
		 * console size: 192 KB
		 * no dump_oops
		 */
		ramoops {
			compatible = "pstore,ramoops";
			mem-size = <0x40000>;
			mem-address = <0x8100000>;
			record-size = <0x8000>;
			console-size = <0x30000>;
			dump-oops = <0>;
			status = "okay";
		};
	};

	sound {
		compatible = "marvell,pxa-88pm805-snd-card";
		ssp-controllers = <&ssp_dai1 &ssp_dai4>;
	};

	ion {
		marvell,ion-nr = <2>;
		status = "okay";
		heap1 {
			marvell,ion-name = "carveout_heap";
			marvell,ion-type = <2>;
			marvell,ion-id = <2>;
			marvell,ion-base = <0x09000000>;
			marvell,ion-size = <0x01000000>;
		};
		heap2 {
			marvell,ion-name = "system_heap";
			marvell,ion-type = <0>;
			marvell,ion-id = <0>;
		};
	};

	panel0: nt35565 {
		compatible = "marvell,mmp-nt35565";
		pinctrl-names = "default";
		pinctrl-0 = <&lcd_pmx_rst>;
		marvell,path-name = "mmp_pnpath";
		rst_gpio = <&gpio 1 0>;
		bl_gpio = <&gpio 32 0>;
		iovdd-supply = <&ldo15>;
		avdd-supply = <&ldo8>;
		status = "okay";
	};

	panel1: lg4591 {
		compatible = "marvell,mmp-lg4591";
		marvell,path-name = "mmp_pnpath";
		panel_esd = <1>;
		rst_gpio = <&gpio 1 0>;
		iovdd-supply = <&ldo15>;
		avdd-supply = <&ldo8>;
		status = "okay";
	};

	panel2: r63311 {
		compatible = "marvell,mmp-r63311";
		marvell,path-name = "mmp_pnpath";
		marvell,ddrfreq-qos = <2>; /* DDR_CONSTRAINT_LVL1 */
		rst_gpio = <&gpio 1 0>;
		iovdd-supply = <&ldo15>;
		power_gpio = <&gpio 107 0>;
		bl_gpio = <&gpio 32 0>;
		status = "okay";
	};

	sd8x-rfkill {
		sd-host = <&sdh2>;
		pd-gpio = <&gpio 7 0>;
		rst-gpio = <&gpio 11 0>;
		status = "okay";
	};

	gps: mmp-gps {
		compatible = "marvell,mmp-gps";
		marvell,gps-eclk-ctrl;

		vgps-supply = <&ldo13>;

		pinctrl-names = "default", "idle";
		pinctrl-0 = <&gps_pmx_eclk>;
		pinctrl-1 = <&gps_pmx_gpio>;

		ldo-en-gpio = <&gpio 20 0>;
		on-off-gpio = <&gpio 96 0>;
		reset-n-gpio = <&gpio 70 0>;
	};

	touch: vnc {
		compatible = "vnc-ts";
	};

	tzdd {
		status = "okay";
	};
	dip {
		compatible = "marvell,simple-dip";
	};
};
